# CY8C5287AXI_LP095 register map
File version: 0.1
CY8C52LP
Registers are 8-bit, read-write, no defined reset value unless marked. A register's access mark holds for its fields unless they carry their own. Offsets are from the block's base; lines under a group give offsets from that group; [hi:lo] are bit positions; {n}, {i} and the like mark numbered series; 'fields as' and 'values as' point back to an identical list; <NAME> marks a mode.

## Memory map
0x00000000 Esp_UART — UART
0x00000000 Debug_UART — UART

## Esp_UART — UART
Base 0x00000000
0x4000642A RX_Esp_UART_RX_ADDRESS1 — RX Address1 Register
0x4000643A RX_Esp_UART_RX_ADDRESS2 — RX Address2 Register
0x40006448 TX_Esp_UART_TX_DATA — TX Data Register
0x4000644A RX_Esp_UART_RX_DATA — RX Data Register
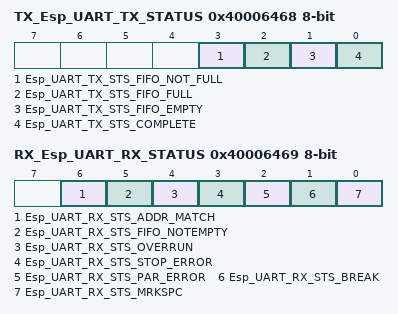
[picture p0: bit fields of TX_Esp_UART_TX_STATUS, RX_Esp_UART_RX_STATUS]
0x40006468 TX_Esp_UART_TX_STATUS — TX status register
  [3] Esp_UART_TX_STS_FIFO_NOT_FULL ro, [2] Esp_UART_TX_STS_FIFO_FULL ro, [1] Esp_UART_TX_STS_FIFO_EMPTY ro, [0] Esp_UART_TX_STS_COMPLETE ro
0x40006469 RX_Esp_UART_RX_STATUS — RX status register
  [6] Esp_UART_RX_STS_ADDR_MATCH ro, [5] Esp_UART_RX_STS_FIFO_NOTEMPTY ro, [4] Esp_UART_RX_STS_OVERRUN ro, [3] Esp_UART_RX_STS_STOP_ERROR ro, [2] Esp_UART_RX_STS_PAR_ERROR ro, [1] Esp_UART_RX_STS_BREAK ro, [0] Esp_UART_RX_STS_MRKSPC ro

## Debug_UART — UART
Base 0x00000000
0x4000652B RX_Debug_UART_RX_ADDRESS1 — RX Address1 Register
0x4000653B RX_Debug_UART_RX_ADDRESS2 — RX Address2 Register
0x40006549 TX_Debug_UART_TX_DATA — TX Data Register
0x4000654B RX_Debug_UART_RX_DATA — RX Data Register
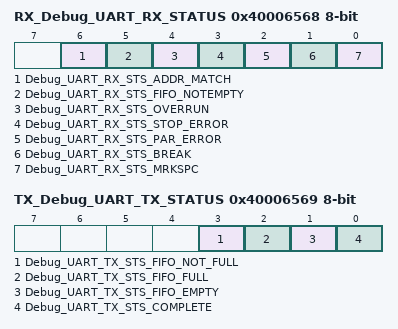
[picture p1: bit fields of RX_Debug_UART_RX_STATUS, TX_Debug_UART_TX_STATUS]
0x40006568 RX_Debug_UART_RX_STATUS — RX status register
  [6] Debug_UART_RX_STS_ADDR_MATCH ro, [5] Debug_UART_RX_STS_FIFO_NOTEMPTY ro, [4] Debug_UART_RX_STS_OVERRUN ro, [3] Debug_UART_RX_STS_STOP_ERROR ro, [2] Debug_UART_RX_STS_PAR_ERROR ro, [1] Debug_UART_RX_STS_BREAK ro, [0] Debug_UART_RX_STS_MRKSPC ro
0x40006569 TX_Debug_UART_TX_STATUS — TX status register
  [3] Debug_UART_TX_STS_FIFO_NOT_FULL ro, [2] Debug_UART_TX_STS_FIFO_FULL ro, [1] Debug_UART_TX_STS_FIFO_EMPTY ro, [0] Debug_UART_TX_STS_COMPLETE ro
